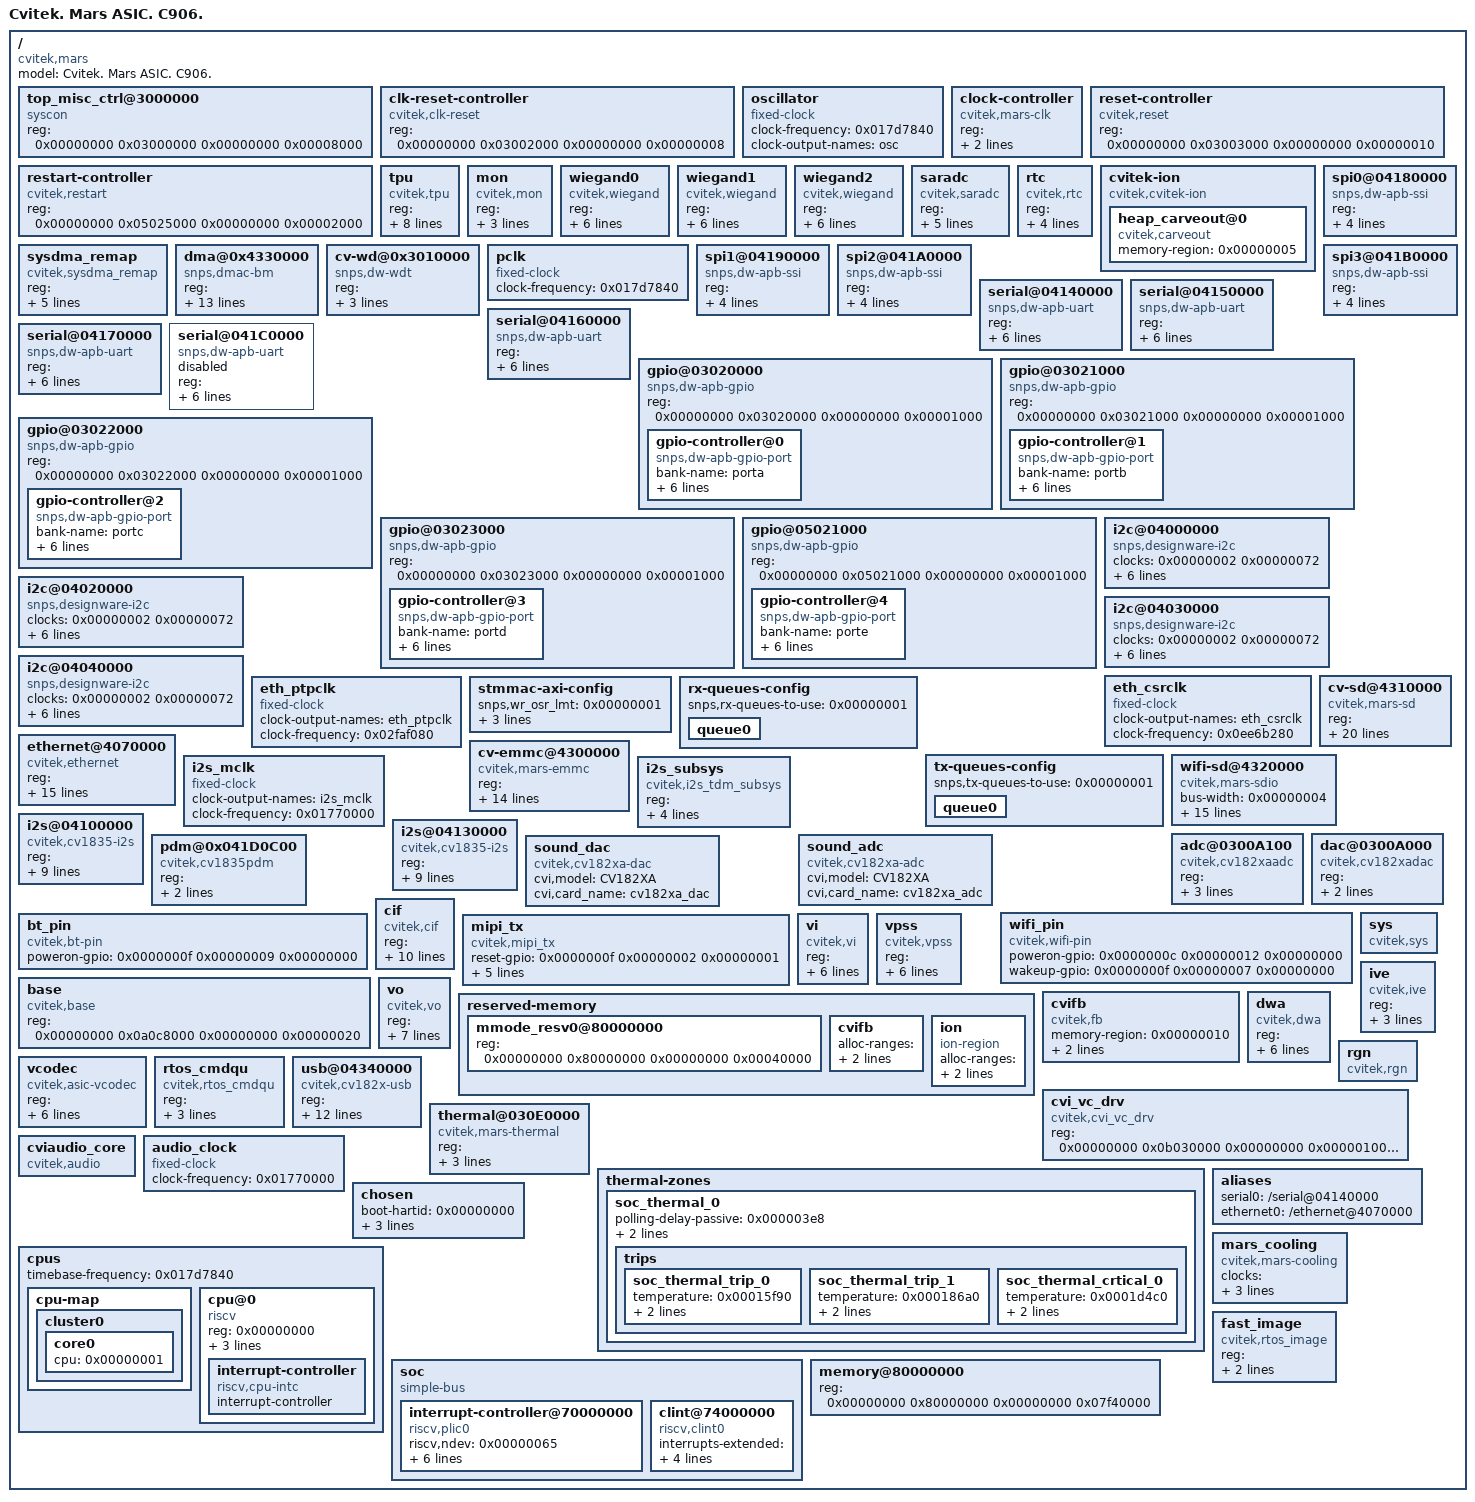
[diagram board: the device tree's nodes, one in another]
/dts-v1/;
// magic:		0xd00dfeed
// totalsize:		0x5000 (20480)
// off_dt_struct:	0x48
// off_dt_strings:	0x4444
// off_mem_rsvmap:	0x28
// version:		17
// last_comp_version:	16
// boot_cpuid_phys:	0x0
// size_dt_strings:	0x652
// size_dt_struct:	0x43fc

/memreserve/ 0x80000000 0x80000;
/ {
    compatible = "cvitek,mars";
    #size-cells = <0x00000002>;
    #address-cells = <0x00000002>;
    model = "Cvitek. Mars ASIC. C906.";
    top_misc_ctrl@3000000 {
        compatible = "syscon";
        reg = <0x00000000 0x03000000 0x00000000 0x00008000>;
    };
    clk-reset-controller {
        #reset-cells = <0x00000001>;
        compatible = "cvitek,clk-reset";
        reg = <0x00000000 0x03002000 0x00000000 0x00000008>;
    };
    oscillator {
        #clock-cells = <0x00000000>;
        compatible = "fixed-clock";
        clock-frequency = <0x017d7840>;
        clock-output-names = "osc";
        phandle = <0x00000001>;
    };
    clock-controller {
        compatible = "cvitek,mars-clk";
        reg = <0x00000000 0x03002000 0x00000000 0x00001000>;
        clocks = <0x00000001>;
        #clock-cells = <0x00000001>;
        phandle = <0x00000002>;
    };
    reset-controller {
        #reset-cells = <0x00000001>;
        compatible = "cvitek,reset";
        reg = <0x00000000 0x03003000 0x00000000 0x00000010>;
        phandle = <0x00000003>;
    };
    restart-controller {
        compatible = "cvitek,restart";
        reg = <0x00000000 0x05025000 0x00000000 0x00002000>;
    };
    tpu {
        compatible = "cvitek,tpu";
        reg-names = "tdma", "tiu";
        reg = <0x00000000 0x0c100000 0x00000000 0x00001000 0x00000000 0x0c101000 0x00000000 0x00001000>;
        clocks = <0x00000002 0x0000000f 0x00000002 0x00000010>;
        clock-names = "clk_tpu_axi", "clk_tpu_fab";
        resets = <0x00000003 0x00000007 0x00000003 0x00000008 0x00000003 0x00000009>;
        reset-names = "res_tdma", "res_tpu", "res_tpusys";
        interrupts = <0x0000004b 0x00000004 0x0000004c 0x00000004>;
        interrupt-names = "tiu_irq", "tdma_irq";
        interrupt-parent = <0x00000004>;
    };
    mon {
        compatible = "cvitek,mon";
        reg-names = "pcmon", "ddr_ctrl", "ddr_phyd", "ddr_aximon", "ddr_top";
        reg = <0x00000000 0x01040000 0x00000000 0x00001000 0x00000000 0x08004000 0x00000000 0x00001000 0x00000000 0x08006000 0x00000000 0x00001000 0x00000000 0x08008000 0x00000000 0x00001000 0x00000000 0x0800a000 0x00000000 0x00001000>;
        interrupts = <0x0000005d 0x00000004>;
        interrupt-names = "mon_irq";
        interrupt-parent = <0x00000004>;
    };
    wiegand0 {
        compatible = "cvitek,wiegand";
        reg-names = "wiegand";
        reg = <0x00000000 0x03030000 0x00000000 0x00001000>;
        clocks = <0x00000002 0x00000081 0x00000002 0x00000082>;
        clock-names = "clk_wgn", "clk_wgn1";
        resets = <0x00000003 0x00000056>;
        reset-names = "res_wgn";
        interrupts = <0x00000040 0x00000004>;
        interrupt-parent = <0x00000004>;
    };
    wiegand1 {
        compatible = "cvitek,wiegand";
        reg-names = "wiegand";
        reg = <0x00000000 0x03031000 0x00000000 0x00001000>;
        clocks = <0x00000002 0x00000081 0x00000002 0x00000083>;
        clock-names = "clk_wgn", "clk_wgn1";
        resets = <0x00000003 0x00000057>;
        reset-names = "res_wgn";
        interrupts = <0x00000041 0x00000004>;
        interrupt-parent = <0x00000004>;
    };
    wiegand2 {
        compatible = "cvitek,wiegand";
        reg-names = "wiegand";
        reg = <0x00000000 0x03032000 0x00000000 0x00001000>;
        clocks = <0x00000002 0x00000081 0x00000002 0x00000084>;
        clock-names = "clk_wgn", "clk_wgn1";
        resets = <0x00000003 0x00000058>;
        reset-names = "res_wgn";
        interrupts = <0x00000042 0x00000004>;
        interrupt-parent = <0x00000004>;
    };
    saradc {
        compatible = "cvitek,saradc";
        reg-names = "top_domain_saradc", "rtc_domain_saradc";
        reg = <0x00000000 0x030f0000 0x00000000 0x00001000 0x00000000 0x0502c000 0x00000000 0x00001000>;
        clocks = <0x00000002 0x00000015>;
        clock-names = "clk_saradc";
        resets = <0x00000003 0x00000034>;
        reset-names = "res_saradc";
        interrupts = <0x00000064 0x00000001>;
        interrupt-parent = <0x00000004>;
    };
    rtc {
        compatible = "cvitek,rtc";
        reg = <0x00000000 0x05026000 0x00000000 0x00001000 0x00000000 0x05025000 0x00000000 0x00001000>;
        clocks = <0x00000002 0x00000013>;
        clock-names = "clk_rtc";
        interrupts = <0x00000011 0x00000004>;
        interrupt-parent = <0x00000004>;
    };
    cvitek-ion {
        compatible = "cvitek,cvitek-ion";
        heap_carveout@0 {
            compatible = "cvitek,carveout";
            memory-region = <0x00000005>;
        };
    };
    sysdma_remap {
        compatible = "cvitek,sysdma_remap";
        reg = <0x00000000 0x03000154 0x00000000 0x00000010>;
        ch-remap = <0x00000000 0x00000005 0x00000002 0x00000003 0x00000026 0x00000026 0x00000004 0x00000007>;
        int_mux_base = <0x03000298>;
        int_mux = <0x0007fc00>;
    };
    dma@0x4330000 {
        compatible = "snps,dmac-bm";
        reg = <0x00000000 0x04330000 0x00000000 0x00001000>;
        clock-names = "clk_sdma_axi";
        clocks = <0x00000002 0x0000002c>;
        dma-channels = [08];
        #dma-cells = <0x00000003>;
        dma-requests = [10];
        chan_allocation_order = [00];
        chan_priority = [01];
        block_size = <0x00000400>;
        dma-masters = [02];
        data-width = <0x00000004 0x00000004>;
        axi_tr_width = <0x00000004>;
        block-ts = <0x0000000f>;
        interrupts = <0x0000001d 0x00000004>;
        interrupt-parent = <0x00000004>;
        phandle = <0x0000000e>;
    };
    cv-wd@0x3010000 {
        compatible = "snps,dw-wdt";
        reg = <0x00000000 0x03010000 0x00000000 0x00001000>;
        resets = <0x00000003 0x00000030>;
        clocks = <0x00000006>;
    };
    pclk {
        #clock-cells = <0x00000000>;
        compatible = "fixed-clock";
        clock-frequency = <0x017d7840>;
        phandle = <0x00000006>;
    };
    spi0@04180000 {
        compatible = "snps,dw-apb-ssi";
        reg = <0x00000000 0x04180000 0x00000000 0x00010000>;
        clocks = <0x00000002 0x00000071>;
        #address-cells = <0x00000001>;
        #size-cells = <0x00000000>;
        interrupts = <0x00000036 0x00000004>;
        interrupt-parent = <0x00000004>;
    };
    spi1@04190000 {
        compatible = "snps,dw-apb-ssi";
        reg = <0x00000000 0x04190000 0x00000000 0x00010000>;
        clocks = <0x00000002 0x00000071>;
        #address-cells = <0x00000001>;
        #size-cells = <0x00000000>;
        interrupts = <0x00000037 0x00000004>;
        interrupt-parent = <0x00000004>;
    };
    spi2@041A0000 {
        compatible = "snps,dw-apb-ssi";
        reg = <0x00000000 0x041a0000 0x00000000 0x00010000>;
        clocks = <0x00000002 0x00000071>;
        #address-cells = <0x00000001>;
        #size-cells = <0x00000000>;
        interrupts = <0x00000038 0x00000004>;
        interrupt-parent = <0x00000004>;
    };
    spi3@041B0000 {
        compatible = "snps,dw-apb-ssi";
        reg = <0x00000000 0x041b0000 0x00000000 0x00010000>;
        clocks = <0x00000002 0x00000071>;
        #address-cells = <0x00000001>;
        #size-cells = <0x00000000>;
        interrupts = <0x00000039 0x00000004>;
        interrupt-parent = <0x00000004>;
    };
    serial@04140000 {
        compatible = "snps,dw-apb-uart";
        reg = <0x00000000 0x04140000 0x00000000 0x00001000>;
        clock-frequency = <0x017d7840>;
        reg-shift = <0x00000002>;
        reg-io-width = <0x00000004>;
        status = "okay";
        interrupts = <0x0000002c 0x00000004>;
        interrupt-parent = <0x00000004>;
    };
    serial@04150000 {
        compatible = "snps,dw-apb-uart";
        reg = <0x00000000 0x04150000 0x00000000 0x00001000>;
        clock-frequency = <0x017d7840>;
        reg-shift = <0x00000002>;
        reg-io-width = <0x00000004>;
        status = "okay";
        interrupts = <0x0000002d 0x00000004>;
        interrupt-parent = <0x00000004>;
    };
    serial@04160000 {
        compatible = "snps,dw-apb-uart";
        reg = <0x00000000 0x04160000 0x00000000 0x00001000>;
        clock-frequency = <0x017d7840>;
        reg-shift = <0x00000002>;
        reg-io-width = <0x00000004>;
        status = "okay";
        interrupts = <0x0000002e 0x00000004>;
        interrupt-parent = <0x00000004>;
    };
    serial@04170000 {
        compatible = "snps,dw-apb-uart";
        reg = <0x00000000 0x04170000 0x00000000 0x00001000>;
        clock-frequency = <0x017d7840>;
        reg-shift = <0x00000002>;
        reg-io-width = <0x00000004>;
        status = "okay";
        interrupts = <0x0000002f 0x00000004>;
        interrupt-parent = <0x00000004>;
    };
    serial@041C0000 {
        compatible = "snps,dw-apb-uart";
        reg = <0x00000000 0x041c0000 0x00000000 0x00001000>;
        clock-frequency = <0x017d7840>;
        reg-shift = <0x00000002>;
        reg-io-width = <0x00000004>;
        status = "disabled";
        interrupts = <0x00000030 0x00000004>;
        interrupt-parent = <0x00000004>;
    };
    gpio@03020000 {
        compatible = "snps,dw-apb-gpio";
        reg = <0x00000000 0x03020000 0x00000000 0x00001000>;
        #address-cells = <0x00000001>;
        #size-cells = <0x00000000>;
        gpio-controller@0 {
            compatible = "snps,dw-apb-gpio-port";
            bank-name = "porta";
            gpio-controller;
            #gpio-cells = <0x00000002>;
            snps,nr-gpios = <0x00000020>;
            reg = <0x00000000>;
            interrupt-controller;
            interrupts = <0x0000003c 0x00000004>;
            interrupt-parent = <0x00000004>;
            phandle = <0x0000000c>;
        };
    };
    gpio@03021000 {
        compatible = "snps,dw-apb-gpio";
        reg = <0x00000000 0x03021000 0x00000000 0x00001000>;
        #address-cells = <0x00000001>;
        #size-cells = <0x00000000>;
        gpio-controller@1 {
            compatible = "snps,dw-apb-gpio-port";
            bank-name = "portb";
            gpio-controller;
            #gpio-cells = <0x00000002>;
            snps,nr-gpios = <0x00000020>;
            reg = <0x00000000>;
            interrupt-controller;
            interrupts = <0x0000003d 0x00000004>;
            interrupt-parent = <0x00000004>;
            phandle = <0x00000011>;
        };
    };
    gpio@03022000 {
        compatible = "snps,dw-apb-gpio";
        reg = <0x00000000 0x03022000 0x00000000 0x00001000>;
        #address-cells = <0x00000001>;
        #size-cells = <0x00000000>;
        gpio-controller@2 {
            compatible = "snps,dw-apb-gpio-port";
            bank-name = "portc";
            gpio-controller;
            #gpio-cells = <0x00000002>;
            snps,nr-gpios = <0x00000020>;
            reg = <0x00000000>;
            interrupt-controller;
            interrupts = <0x0000003e 0x00000004>;
            interrupt-parent = <0x00000004>;
        };
    };
    gpio@03023000 {
        compatible = "snps,dw-apb-gpio";
        reg = <0x00000000 0x03023000 0x00000000 0x00001000>;
        #address-cells = <0x00000001>;
        #size-cells = <0x00000000>;
        gpio-controller@3 {
            compatible = "snps,dw-apb-gpio-port";
            bank-name = "portd";
            gpio-controller;
            #gpio-cells = <0x00000002>;
            snps,nr-gpios = <0x0000000c>;
            reg = <0x00000000>;
            interrupt-controller;
            interrupts = <0x0000003f 0x00000004>;
            interrupt-parent = <0x00000004>;
        };
    };
    gpio@05021000 {
        compatible = "snps,dw-apb-gpio";
        reg = <0x00000000 0x05021000 0x00000000 0x00001000>;
        #address-cells = <0x00000001>;
        #size-cells = <0x00000000>;
        gpio-controller@4 {
            compatible = "snps,dw-apb-gpio-port";
            bank-name = "porte";
            gpio-controller;
            #gpio-cells = <0x00000002>;
            snps,nr-gpios = <0x00000018>;
            reg = <0x00000000>;
            interrupt-controller;
            interrupts = <0x00000046 0x00000004>;
            interrupt-parent = <0x00000004>;
            phandle = <0x0000000f>;
        };
    };
    i2c@04000000 {
        compatible = "snps,designware-i2c";
        clocks = <0x00000002 0x00000072>;
        reg = <0x00000000 0x04000000 0x00000000 0x00001000>;
        clock-frequency = <0x00061a80>;
        #size-cells = <0x00000000>;
        #address-cells = <0x00000001>;
        resets = <0x00000003 0x0000001b>;
        reset-names = "i2c0";
        interrupts = <0x00000031 0x00000004>;
        interrupt-parent = <0x00000004>;
    };
    i2c@04020000 {
        compatible = "snps,designware-i2c";
        clocks = <0x00000002 0x00000072>;
        reg = <0x00000000 0x04020000 0x00000000 0x00001000>;
        clock-frequency = <0x000186a0>;
        resets = <0x00000003 0x0000001d>;
        reset-names = "i2c2";
        interrupts = <0x00000033 0x00000004>;
        interrupt-parent = <0x00000004>;
    };
    i2c@04030000 {
        compatible = "snps,designware-i2c";
        clocks = <0x00000002 0x00000072>;
        reg = <0x00000000 0x04030000 0x00000000 0x00001000>;
        clock-frequency = <0x00061a80>;
        resets = <0x00000003 0x0000001e>;
        reset-names = "i2c3";
        interrupts = <0x00000034 0x00000004>;
        interrupt-parent = <0x00000004>;
    };
    i2c@04040000 {
        compatible = "snps,designware-i2c";
        clocks = <0x00000002 0x00000072>;
        reg = <0x00000000 0x04040000 0x00000000 0x00001000>;
        clock-frequency = <0x00061a80>;
        resets = <0x00000003 0x0000001f>;
        reset-names = "i2c4";
        interrupts = <0x00000035 0x00000004>;
        interrupt-parent = <0x00000004>;
    };
    eth_csrclk {
        clock-output-names = "eth_csrclk";
        clock-frequency = <0x0ee6b280>;
        #clock-cells = <0x00000000>;
        compatible = "fixed-clock";
        phandle = <0x00000007>;
    };
    eth_ptpclk {
        clock-output-names = "eth_ptpclk";
        clock-frequency = <0x02faf080>;
        #clock-cells = <0x00000000>;
        compatible = "fixed-clock";
        phandle = <0x00000008>;
    };
    stmmac-axi-config {
        snps,wr_osr_lmt = <0x00000001>;
        snps,rd_osr_lmt = <0x00000002>;
        snps,blen = <0x00000004 0x00000008 0x00000010 0x00000000 0x00000000 0x00000000 0x00000000>;
        phandle = <0x00000009>;
    };
    rx-queues-config {
        snps,rx-queues-to-use = <0x00000001>;
        phandle = <0x0000000a>;
        queue0 {
        };
    };
    tx-queues-config {
        snps,tx-queues-to-use = <0x00000001>;
        phandle = <0x0000000b>;
        queue0 {
        };
    };
    ethernet@4070000 {
        compatible = "cvitek,ethernet";
        reg = <0x00000000 0x04070000 0x00000000 0x00010000>;
        clock-names = "stmmaceth", "ptp_ref";
        clocks = <0x00000007 0x00000008>;
        tx-fifo-depth = <0x00002000>;
        rx-fifo-depth = <0x00002000>;
        snps,multicast-filter-bins = <0x00000000>;
        snps,perfect-filter-entries = <0x00000001>;
        snps,txpbl = <0x00000008>;
        snps,rxpbl = <0x00000008>;
        snps,aal;
        snps,axi-config = <0x00000009>;
        snps,mtl-rx-config = <0x0000000a>;
        snps,mtl-tx-config = <0x0000000b>;
        phy-mode = "rmii";
        interrupt-names = "macirq";
        interrupts = <0x0000001f 0x00000004>;
        interrupt-parent = <0x00000004>;
    };
    cv-emmc@4300000 {
        compatible = "cvitek,mars-emmc";
        reg = <0x00000000 0x04300000 0x00000000 0x00001000>;
        reg-names = "core_mem";
        bus-width = <0x00000004>;
        non-removable;
        no-sdio;
        no-sd;
        src-frequency = <0x165a0bc0>;
        min-frequency = <0x00061a80>;
        max-frequency = <0x0bebc200>;
        64_addressing;
        reset_tx_rx_phy;
        pll_index = <0x00000005>;
        pll_reg = <0x03002064>;
        interrupts = <0x00000022 0x00000004>;
        interrupt-parent = <0x00000004>;
    };
    cv-sd@4310000 {
        compatible = "cvitek,mars-sd";
        reg = <0x00000000 0x04310000 0x00000000 0x00001000>;
        reg-names = "core_mem";
        bus-width = <0x00000004>;
        cap-sd-highspeed;
        cap-mmc-highspeed;
        sd-uhs-sdr12;
        sd-uhs-sdr25;
        sd-uhs-sdr50;
        sd-uhs-sdr104;
        no-sdio;
        no-mmc;
        src-frequency = <0x165a0bc0>;
        min-frequency = <0x00061a80>;
        max-frequency = <0x0bebc200>;
        64_addressing;
        reset_tx_rx_phy;
        reset-names = "sdhci";
        pll_index = <0x00000006>;
        pll_reg = <0x03002070>;
        cvi-cd-gpios = <0x0000000c 0x0000000d 0x00000001>;
        interrupts = <0x00000024 0x00000004>;
        interrupt-parent = <0x00000004>;
    };
    wifi-sd@4320000 {
        compatible = "cvitek,mars-sdio";
        bus-width = <0x00000004>;
        reg = <0x00000000 0x04320000 0x00000000 0x00001000>;
        reg_names = "core_mem";
        src-frequency = <0x165a0bc0>;
        min-frequency = <0x00061a80>;
        max-frequency = <0x02faf080>;
        64_addressing;
        reset_tx_rx_phy;
        non-removable;
        pll_index = <0x00000007>;
        pll_reg = <0x0300207c>;
        no-mmc;
        no-sd;
        status = "okay";
        interrupts = <0x00000026 0x00000004>;
        interrupt-parent = <0x00000004>;
    };
    i2s_mclk {
        clock-output-names = "i2s_mclk";
        clock-frequency = <0x01770000>;
        #clock-cells = <0x00000000>;
        compatible = "fixed-clock";
        phandle = <0x0000000d>;
    };
    i2s_subsys {
        compatible = "cvitek,i2s_tdm_subsys";
        reg = <0x00000000 0x04108000 0x00000000 0x00000100>;
        clocks = <0x0000000d 0x00000002 0x00000004 0x00000002 0x0000002d 0x00000002 0x0000002e 0x00000002 0x0000002f 0x00000002 0x00000030>;
        clock-names = "i2sclk", "clk_a0pll", "clk_sdma_aud0", "clk_sdma_aud1", "clk_sdma_aud2", "clk_sdma_aud3";
        master_base = <0x04110000>;
    };
    i2s@04100000 {
        compatible = "cvitek,cv1835-i2s";
        reg = <0x00000000 0x04100000 0x00000000 0x00002000>;
        clocks = <0x0000000d 0x00000000>;
        clock-names = "i2sclk";
        dev-id = <0x00000000>;
        #sound-dai-cells = <0x00000000>;
        dmas = <0x0000000e 0x00000000 0x00000001 0x00000001>;
        dma-names = "rx";
        capability = "rx";
        mclk_out = "false";
        interrupts = <0x00000028 0x00000004>;
        interrupt-parent = <0x00000004>;
    };
    i2s@04130000 {
        compatible = "cvitek,cv1835-i2s";
        reg = <0x00000000 0x04130000 0x00000000 0x00002000>;
        clocks = <0x0000000d 0x00000000>;
        clock-names = "i2sclk";
        dev-id = <0x00000003>;
        #sound-dai-cells = <0x00000000>;
        dmas = <0x0000000e 0x00000007 0x00000001 0x00000001>;
        dma-names = "tx";
        capability = "tx";
        mclk_out = "true";
        interrupts = <0x0000002b 0x00000004>;
        interrupt-parent = <0x00000004>;
    };
    adc@0300A100 {
        compatible = "cvitek,cv182xaadc";
        reg = <0x00000000 0x0300a100 0x00000000 0x00000100>;
        clocks = <0x0000000d 0x00000000>;
        clock-names = "i2sclk";
        clk_source = <0x04130000>;
    };
    dac@0300A000 {
        compatible = "cvitek,cv182xadac";
        reg = <0x00000000 0x0300a000 0x00000000 0x00000100>;
        clocks = <0x0000000d 0x00000000>;
        clock-names = "i2sclk";
    };
    pdm@0x041D0C00 {
        compatible = "cvitek,cv1835pdm";
        reg = <0x00000000 0x041d0c00 0x00000000 0x00000100>;
        clocks = <0x0000000d 0x00000000>;
        clock-names = "i2sclk";
    };
    sound_adc {
        compatible = "cvitek,cv182xa-adc";
        cvi,model = "CV182XA";
        cvi,card_name = "cv182xa_adc";
    };
    sound_dac {
        compatible = "cvitek,cv182xa-dac";
        cvi,model = "CV182XA";
        cvi,card_name = "cv182xa_dac";
    };
    wifi_pin {
        compatible = "cvitek,wifi-pin";
        poweron-gpio = <0x0000000c 0x00000012 0x00000000>;
        wakeup-gpio = <0x0000000f 0x00000007 0x00000000>;
    };
    bt_pin {
        compatible = "cvitek,bt-pin";
        poweron-gpio = <0x0000000f 0x00000009 0x00000000>;
    };
    cif {
        compatible = "cvitek,cif";
        reg = <0x00000000 0x0a0c2000 0x00000000 0x00002000 0x00000000 0x0a0d0000 0x00000000 0x00001000 0x00000000 0x0a0c4000 0x00000000 0x00002000 0x00000000 0x0a0c6000 0x00000000 0x00002000 0x00000000 0x03001c30 0x00000000 0x00000030>;
        reg-names = "csi_mac0", "csi_wrap0", "csi_mac1", "csi_mac2", "pad_ctrl";
        snsr-reset = <0x0000000c 0x00000002 0x00000001 0x0000000c 0x00000006 0x00000001 0x0000000c 0x00000002 0x00000001>;
        resets = <0x00000003 0x00000046 0x00000003 0x00000048 0x00000003 0x00000047 0x00000003 0x00000049>;
        reset-names = "phy0", "phy1", "phy-apb0", "phy-apb1";
        clocks = <0x00000002 0x0000005b 0x00000002 0x0000005c 0x00000002 0x00000088 0x00000002 0x00000003 0x00000002 0x00000005 0x00000002 0x00000002>;
        clock-names = "clk_cam0", "clk_cam1", "clk_sys_2", "clk_mipimpll", "clk_disppll", "clk_fpll";
        interrupts = <0x0000001a 0x00000004 0x0000001b 0x00000004>;
        interrupt-names = "csi0", "csi1";
        interrupt-parent = <0x00000004>;
    };
    mipi_tx {
        compatible = "cvitek,mipi_tx";
        reset-gpio = <0x0000000f 0x00000002 0x00000001>;
        pwm-gpio = <0x0000000f 0x00000000 0x00000000>;
        power-ct-gpio = <0x0000000f 0x00000001 0x00000000>;
        clocks = <0x00000002 0x00000069 0x00000002 0x0000006a>;
        clock-names = "clk_disp", "clk_dsi";
    };
    sys {
        compatible = "cvitek,sys";
    };
    base {
        compatible = "cvitek,base";
        reg = <0x00000000 0x0a0c8000 0x00000000 0x00000020>;
        reg-names = "vip_sys";
    };
    vi {
        compatible = "cvitek,vi";
        reg = <0x00000000 0x0a000000 0x00000000 0x00080000>;
        clocks = <0x00000002 0x00000050 0x00000002 0x00000051 0x00000002 0x00000088 0x00000002 0x0000009a 0x00000002 0x0000004f 0x00000002 0x00000093 0x00000002 0x0000009d 0x00000002 0x0000005f 0x00000002 0x0000005d 0x00000002 0x0000005e 0x00000002 0x0000009f>;
        clock-names = "clk_sys_0", "clk_sys_1", "clk_sys_2", "clk_sys_3", "clk_axi", "clk_csi_be", "clk_raw", "clk_isp_top", "clk_csi_mac0", "clk_csi_mac1", "clk_csi_mac2";
        clock-freq-vip-sys1 = <0x11e1a300>;
        interrupts = <0x00000018 0x00000004>;
        interrupt-parent = <0x00000004>;
        interrupt-names = "isp";
    };
    vpss {
        compatible = "cvitek,vpss";
        reg = <0x00000000 0x0a080000 0x00000000 0x00010000 0x00000000 0x0a0d1000 0x00000000 0x00000100>;
        reg-names = "sc";
        clocks = <0x00000002 0x00000050 0x00000002 0x00000051 0x00000002 0x00000088 0x00000002 0x00000060 0x00000002 0x00000061 0x00000002 0x00000062 0x00000002 0x00000063 0x00000002 0x00000064 0x00000002 0x00000065 0x00000002 0x00000066>;
        clock-names = "clk_sys_0", "clk_sys_1", "clk_sys_2", "clk_img_d", "clk_img_v", "clk_sc_top", "clk_sc_d", "clk_sc_v1", "clk_sc_v2", "clk_sc_v3";
        clock-freq-vip-sys1 = <0x11e1a300>;
        interrupts = <0x00000019 0x00000004>;
        interrupt-names = "sc";
        interrupt-parent = <0x00000004>;
    };
    ive {
        compatible = "cvitek,ive";
        reg = <0x00000000 0x0a0a0000 0x00000000 0x00003100>;
        reg-names = "ive_base";
        interrupt-names = "ive_irq";
        interrupt-parent = <0x00000004>;
        interrupts = <0x00000061 0x00000004>;
    };
    vo {
        compatible = "cvitek,vo";
        reg = <0x00000000 0x0a080000 0x00000000 0x00010000 0x00000000 0x0a0c8000 0x00000000 0x000000a0 0x00000000 0x0a0d1000 0x00000000 0x00000100>;
        reg-names = "sc", "vip_sys", "dphy";
        clocks = <0x00000002 0x00000069 0x00000002 0x0000006a 0x00000002 0x00000068>;
        reset-gpio = <0x0000000f 0x00000002 0x00000001>;
        pwm-gpio = <0x0000000f 0x00000000 0x00000000>;
        power-ct-gpio = <0x0000000f 0x00000001 0x00000000>;
        clock-names = "clk_disp", "clk_dsi", "clk_bt";
    };
    reserved-memory {
        #size-cells = <0x00000002>;
        #address-cells = <0x00000002>;
        ranges;
        mmode_resv0@80000000 {
            reg = <0x00000000 0x80000000 0x00000000 0x00040000>;
            phandle = <0x00000014>;
        };
        cvifb {
            alloc-ranges = <0x00000000 0x8377e000 0x00000000 0x001c2000>;
            size = <0x00000000 0x001c2000>;
            phandle = <0x00000010>;
        };
        ion {
            compatible = "ion-region";
            alloc-ranges = <0x00000000 0x83940000 0x00000000 0x04600000>;
            size = <0x00000000 0x04600000>;
            phandle = <0x00000005>;
        };
    };
    cvifb {
        compatible = "cvitek,fb";
        memory-region = <0x00000010>;
        reg = <0x00000000 0x0a088000 0x00000000 0x00001000>;
        reg-names = "disp";
    };
    dwa {
        compatible = "cvitek,dwa";
        reg = <0x00000000 0x0a0c0000 0x00000000 0x00001000>;
        reg-names = "dwa";
        clocks = <0x00000002 0x00000050 0x00000002 0x00000051 0x00000002 0x00000088 0x00000002 0x0000009a 0x00000002 0x0000009b 0x00000002 0x00000067>;
        clock-names = "clk_sys_0", "clk_sys_1", "clk_sys_2", "clk_sys_3", "clk_sys_4", "clk_dwa";
        clock-freq-vip-sys1 = <0x11e1a300>;
        interrupts = <0x0000001c 0x00000004>;
        interrupt-names = "dwa";
        interrupt-parent = <0x00000004>;
    };
    rgn {
        compatible = "cvitek,rgn";
    };
    vcodec {
        compatible = "cvitek,asic-vcodec";
        reg = <0x00000000 0x0b020000 0x00000000 0x00010000 0x00000000 0x0b010000 0x00000000 0x00010000 0x00000000 0x0b030000 0x00000000 0x00000100 0x00000000 0x0b058000 0x00000000 0x00000100 0x00000000 0x0b050000 0x00000000 0x00000400>;
        reg-names = "h265", "h264", "vc_ctrl", "vc_sbm", "vc_addr_remap";
        clocks = <0x00000002 0x00000053 0x00000002 0x00000055 0x00000002 0x00000059 0x00000002 0x00000056 0x00000002 0x0000005a 0x00000002 0x00000054 0x00000002 0x00000087 0x00000002 0x0000008e 0x00000002 0x0000008b>;
        clock-names = "clk_axi_video_codec", "clk_h264c", "clk_apb_h264c", "clk_h265c", "clk_apb_h265c", "clk_vc_src0", "clk_vc_src1", "clk_vc_src2", "clk_cfg_reg_vc";
        interrupts = <0x00000016 0x00000004 0x00000015 0x00000004 0x00000017 0x00000004>;
        interrupt-names = "h265", "h264", "sbm";
        interrupt-parent = <0x00000004>;
    };
    cvi_vc_drv {
        compatible = "cvitek,cvi_vc_drv";
        reg = <0x00000000 0x0b030000 0x00000000 0x00000100 0x00000000 0x0b058000 0x00000000 0x00000100 0x00000000 0x0b050000 0x00000000 0x00000400>;
        reg-names = "vc_ctrl", "vc_sbm", "vc_addr_remap";
    };
    rtos_cmdqu {
        compatible = "cvitek,rtos_cmdqu";
        reg = <0x00000000 0x01900000 0x00000000 0x00001000>;
        reg-names = "mailbox";
        interrupts = <0x00000065 0x00000004>;
        interrupt-names = "mailbox";
        interrupt-parent = <0x00000004>;
    };
    usb@04340000 {
        compatible = "cvitek,cv182x-usb";
        reg = <0x00000000 0x04340000 0x00000000 0x00010000 0x00000000 0x03006000 0x00000000 0x00000058>;
        dr_mode = "otg";
        g-use-dma;
        g-rx-fifo-size = <0x00000218>;
        g-np-tx-fifo-size = <0x00000020>;
        g-tx-fifo-size = <0x00000300 0x00000200 0x00000200 0x00000180 0x00000080 0x00000080>;
        clocks = <0x00000002 0x00000047 0x00000002 0x00000048 0x00000002 0x00000049 0x00000002 0x0000004a 0x00000002 0x0000004b>;
        clock-names = "clk_axi", "clk_apb", "clk_125m", "clk_33k", "clk_12m";
        vbus-gpio = <0x00000011 0x00000006 0x00000000>;
        status = "okay";
        interrupts = <0x0000001e 0x00000004>;
        interrupt-parent = <0x00000004>;
    };
    thermal@030E0000 {
        compatible = "cvitek,mars-thermal";
        reg = <0x00000000 0x030e0000 0x00000000 0x00010000>;
        clocks = <0x00000002 0x00000014>;
        clock-names = "clk_tempsen";
        reset-names = "tempsen";
        #thermal-sensor-cells = <0x00000001>;
        interrupts = <0x00000010 0x00000004>;
        interrupt-names = "tempsen";
        phandle = <0x00000012>;
    };
    thermal-zones {
        soc_thermal_0 {
            polling-delay-passive = <0x000003e8>;
            polling-delay = <0x000003e8>;
            thermal-sensors = <0x00000012 0x00000000>;
            trips {
                soc_thermal_trip_0 {
                    temperature = <0x00015f90>;
                    hysteresis = <0x00001388>;
                    type = "passive";
                };
                soc_thermal_trip_1 {
                    temperature = <0x000186a0>;
                    hysteresis = <0x00001388>;
                    type = "passive";
                };
                soc_thermal_crtical_0 {
                    temperature = <0x0001d4c0>;
                    hysteresis = <0x00000000>;
                    type = "critical";
                };
            };
        };
    };
    cviaudio_core {
        compatible = "cvitek,audio";
    };
    audio_clock {
        compatible = "fixed-clock";
        #clock-cells = <0x00000000>;
        clock-frequency = <0x01770000>;
    };
    aliases {
        serial0 = "/serial@04140000";
        ethernet0 = "/ethernet@4070000";
    };
    chosen {
        boot-hartid = <0x00000000>;
        bootargs = "rootfstype=squashfs rootwait ro root=/dev/mmcblk0p4 blkdevparts=mmcblk0:8192K(BOOT),512K(MISC),128K(ENV),70656K(ROOTFS),40960K(SYSTEM),15240K(CFG),3145728K(DATA);mmcblk0boot0:1M(fip),1M(fip_bak); console=ttyS0,115200 earlycon=sbi loglevel=9 riscv.fwsz=0x80000";
        stdout-path = "serial0";
    };
    cpus {
        #address-cells = <0x00000001>;
        #size-cells = <0x00000000>;
        timebase-frequency = <0x017d7840>;
        cpu-map {
            cluster0 {
                core0 {
                    cpu = <0x00000001>;
                };
            };
        };
        cpu@0 {
            device_type = "cpu";
            reg = <0x00000000>;
            status = "okay";
            compatible = "riscv";
            riscv,isa = "rv64imafdvcsu";
            mmu-type = "riscv,sv39";
            clock-frequency = <0x017d7840>;
            interrupt-controller {
                #interrupt-cells = <0x00000001>;
                interrupt-controller;
                compatible = "riscv,cpu-intc";
                phandle = <0x00000013>;
            };
        };
    };
    soc {
        #address-cells = <0x00000002>;
        #size-cells = <0x00000002>;
        compatible = "simple-bus";
        ranges;
        interrupt-controller@70000000 {
            riscv,ndev = <0x00000065>;
            riscv,max-priority = <0x00000007>;
            reg-names = "control";
            reg = <0x00000000 0x70000000 0x00000000 0x04000000>;
            interrupts-extended = <0x00000013 0xffffffff 0x00000013 0x00000009>;
            interrupt-controller;
            compatible = "riscv,plic0";
            #interrupt-cells = <0x00000002>;
            #address-cells = <0x00000000>;
            phandle = <0x00000004>;
        };
        clint@74000000 {
            interrupts-extended = <0x00000013 0x00000003 0x00000013 0x00000007>;
            reg = <0x00000000 0x74000000 0x00000000 0x00010000>;
            compatible = "riscv,clint0";
            clint,has-no-64bit-mmio;
        };
    };
    mars_cooling {
        clocks = <0x00000002 0x00000098 0x00000002 0x0000000f>;
        clock-names = "clk_cpu", "clk_tpu_axi";
        dev-freqs = <0x32a9f880 0x1dcd6500 0x1954fc40 0x165a0bc0 0x1954fc40 0x11e1a300>;
        compatible = "cvitek,mars-cooling";
        #cooling-cells = <0x00000002>;
    };
    memory@80000000 {
        device_type = "memory";
        reg = <0x00000000 0x80000000 0x00000000 0x07f40000>;
    };
    fast_image {
        compatible = "cvitek,rtos_image";
        reg-names = "rtos_region";
        reg = <0x00000000 0x87f40000 0x00000000 0x000c0000>;
        ion-size = <0x01600000>;
    };
};
